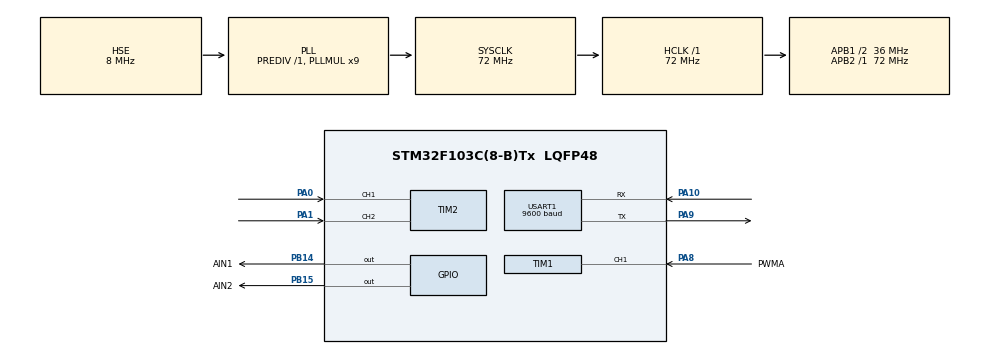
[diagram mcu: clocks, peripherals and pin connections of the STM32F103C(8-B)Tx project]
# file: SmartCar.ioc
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Mcu.Family=STM32F1
Mcu.Name=STM32F103C(8-B)Tx
Mcu.Package=LQFP48
NVIC.PriorityGroup=NVIC_PRIORITYGROUP_4
NVIC.TIM3_IRQn=true\:0\:0\:false\:false\:true\:true\:true\:true
NVIC.USART1_IRQn=true\:0\:0\:false\:false\:true\:true\:true\:true
PA0-WKUP.Signal=S_TIM2_CH1_ETR
PA1.Signal=S_TIM2_CH2
PA10.Mode=Asynchronous
PA10.Signal=USART1_RX
PA13.Mode=Serial_Wire
PA13.Signal=SYS_JTMS-SWDIO
PA14.Mode=Serial_Wire
PA14.Signal=SYS_JTCK-SWCLK
PA8.GPIO_Label=PWMA
PA8.GPIO_PuPd=GPIO_PULLUP
PA8.Signal=S_TIM1_CH1
PA9.Mode=Asynchronous
PA9.Signal=USART1_TX
PB14.GPIO_Label=AIN1
PB14.GPIO_PuPd=GPIO_PULLUP
PB14.Signal=GPIO_Output
PB15.GPIO_Label=AIN2
PB15.GPIO_ModeDefaultOutputPP=GPIO_MODE_OUTPUT_PP
PB15.GPIO_PuPd=GPIO_PULLUP
PB15.Signal=GPIO_Output
PC14-OSC32_IN.Mode=LSE-External-Oscillator
PC14-OSC32_IN.Signal=RCC_OSC32_IN
PC15-OSC32_OUT.Mode=LSE-External-Oscillator
PC15-OSC32_OUT.Signal=RCC_OSC32_OUT
PD0-OSC_IN.Mode=HSE-External-Oscillator
PD0-OSC_IN.Signal=RCC_OSC_IN
PD1-OSC_OUT.Mode=HSE-External-Oscillator
PD1-OSC_OUT.Signal=RCC_OSC_OUT
ProjectManager.HeapSize=0x200
ProjectManager.StackSize=0x400
ProjectManager.TargetToolchain=MDK-ARM V5.32
RCC.AHBFreq_Value=72000000
RCC.APB1CLKDivider=RCC_HCLK_DIV2
RCC.APB1Freq_Value=36000000
RCC.APB1TimFreq_Value=72000000
RCC.APB2Freq_Value=72000000
RCC.APB2TimFreq_Value=72000000
RCC.HCLKFreq_Value=72000000
RCC.PLLMUL=RCC_PLL_MUL9
RCC.PLLSourceVirtual=RCC_PLLSOURCE_HSE
RCC.SYSCLKFreq_VALUE=72000000
RCC.SYSCLKSource=RCC_SYSCLKSOURCE_PLLCLK
RCC.USBFreq_Value=72000000
SH.S_TIM1_CH1.0=TIM1_CH1,PWM_Input_1
SH.S_TIM2_CH1_ETR.0=TIM2_CH1,Encoder_Interface
SH.S_TIM2_CH2.0=TIM2_CH2,Encoder_Interface
TIM1.Period=2400
TIM1.Prescaler=3-1
TIM2.EncoderMode=TIM_ENCODERMODE_TI12
TIM2.IC1Filter=15
TIM2.IC2Filter=15
TIM3.AutoReloadPreload=TIM_AUTORELOAD_PRELOAD_ENABLE
TIM3.Period=100-1
TIM3.Prescaler=7199
USART1.BaudRate=9600
USART1.VirtualMode=VM_ASYNC
VP_TIM3_VS_ClockSourceINT.Mode=Internal
board=custom

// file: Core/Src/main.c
/* USER CODE BEGIN Header */
/**
  ******************************************************************************
  * @file           : main.c
  * @brief          : Main program body
  ******************************************************************************
  * @attention
  *
  * Copyright (c) 2025 STMicroelectronics.
  * All rights reserved.
  *
  * This software is licensed under terms that can be found in the LICENSE file
  * in the root directory of this software component.
  * If no LICENSE file comes with this software, it is provided AS-IS.
  *
  ******************************************************************************
  */
/* USER CODE END Header */
#include "main.h"
#include "tim.h"
#include "usart.h"
#include "gpio.h"

/* USER CODE BEGIN Includes */
#include "stdio.h"
#include "moter.h"
/* USER CODE END Includes */

void SystemClock_Config(void);

int main(void)
{

  /* MCU Configuration--------------------------------------------------------*/

  /* Reset of all peripherals, Initializes the Flash interface and the Systick. */
  HAL_Init();

  /* Configure the system clock */
  SystemClock_Config();

  /* Initialize all configured peripherals */
  MX_GPIO_Init();
  MX_TIM2_Init();
  MX_USART1_UART_Init();
  MX_TIM1_Init();
  MX_TIM3_Init();
  /* USER CODE BEGIN 2 */
	HAL_TIM_PWM_Start(&htim1,TIM_CHANNEL_1);
	HAL_TIM_Base_Start_IT(&htim3);
	HAL_TIM_Encoder_Start(&htim2,TIM_CHANNEL_1|TIM_CHANNEL_2);//定时器编码器启动
	uint8_t direction=2;//转圈的方向
	int16_t counter;//定时器计数，16位定时器int16_t

	float rotation=0;//圈数
	float distance=0;
	float speed_w=0;
	float speed_V=0;
	int16_t counter_last;

  /* USER CODE END 2 */

  /* Infinite loop */
  /* USER CODE BEGIN WHILE */
  while (1)
  {

//	  direction=__HAL_TIM_IS_TIM_COUNTING_DOWN(&htim2);
//	  counter=(int16_t)__HAL_TIM_GET_COUNTER(&htim2);
//	  rotation=(float)counter/(21.3*11*4);//ppr*减速比*4（上升沿下降沿计数）
//	  distance=rotation*3.1415926*0.065;//走的距离
//	  speed_w=(float)(counter-counter_last)/(21.3*11*4)*1000/10*60;//角速度
//	  speed_V=speed_w/60*3.1415926*0.065;//线速度，轮直径0.065M；
//	  //printf("dir:%d,%d,%.2f,%.2f\n",direction,counter,rotation,distance);
//
//	  //printf("%.2f,%.2f\n",speed_w,speed_V);
//	  counter_last=counter;
//	  //HAL_Delay(10);
    /* USER CODE END WHILE */

  }
}

void SystemClock_Config(void)
{
  RCC_OscInitTypeDef RCC_OscInitStruct = {0};
  RCC_ClkInitTypeDef RCC_ClkInitStruct = {0};

  /** Initializes the RCC Oscillators according to the specified parameters
  * in the RCC_OscInitTypeDef structure.
  */
  RCC_OscInitStruct.OscillatorType = RCC_OSCILLATORTYPE_HSE;
  RCC_OscInitStruct.HSEState = RCC_HSE_ON;
  RCC_OscInitStruct.HSEPredivValue = RCC_HSE_PREDIV_DIV1;
  RCC_OscInitStruct.HSIState = RCC_HSI_ON;
  RCC_OscInitStruct.PLL.PLLState = RCC_PLL_ON;
  RCC_OscInitStruct.PLL.PLLSource = RCC_PLLSOURCE_HSE;
  RCC_OscInitStruct.PLL.PLLMUL = RCC_PLL_MUL9;
  if (HAL_RCC_OscConfig(&RCC_OscInitStruct) != HAL_OK)
  {
    Error_Handler();
  }

  /** Initializes the CPU, AHB and APB buses clocks
  */
  RCC_ClkInitStruct.ClockType = RCC_CLOCKTYPE_HCLK|RCC_CLOCKTYPE_SYSCLK
                              |RCC_CLOCKTYPE_PCLK1|RCC_CLOCKTYPE_PCLK2;
  RCC_ClkInitStruct.SYSCLKSource = RCC_SYSCLKSOURCE_PLLCLK;
  RCC_ClkInitStruct.AHBCLKDivider = RCC_SYSCLK_DIV1;
  RCC_ClkInitStruct.APB1CLKDivider = RCC_HCLK_DIV2;
  RCC_ClkInitStruct.APB2CLKDivider = RCC_HCLK_DIV1;

  if (HAL_RCC_ClockConfig(&RCC_ClkInitStruct, FLASH_LATENCY_2) != HAL_OK)
  {
    Error_Handler();
  }
}

void Error_Handler(void)
{
  __disable_irq();
  while (1)
  {
  }
}
